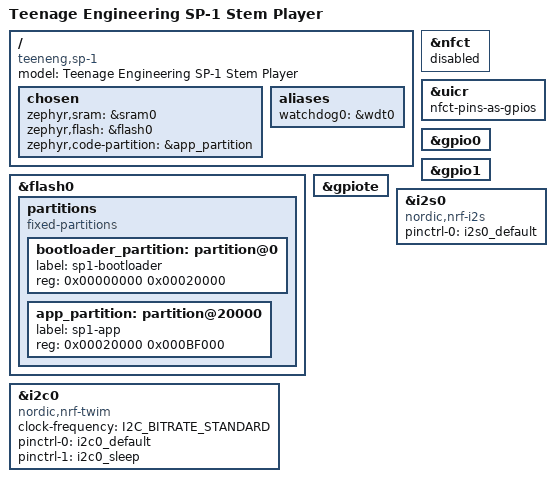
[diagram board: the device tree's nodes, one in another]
/dts-v1/;
#include <nordic/nrf52840_qiaa.dtsi>
#include "sp1-pinctrl.dtsi"

/ {
	model = "Teenage Engineering SP-1 Stem Player";
	compatible = "teeneng,sp-1";

	chosen {
		zephyr,sram = &sram0;
		zephyr,flash = &flash0;
		zephyr,code-partition = &app_partition;
	};

	aliases {
		watchdog0 = &wdt0;
	};
};

&flash0 {
	partitions {
		compatible = "fixed-partitions";
		#address-cells = <1>;
		#size-cells = <1>;

		bootloader_partition: partition@0 {
			label = "sp1-bootloader";
			reg = <0x00000000 0x00020000>;
		};

		app_partition: partition@20000 {
			label = "sp1-app";
			reg = <0x00020000 0x000BF000>;
		};
	};
};

&nfct {
	status = "disabled";
};

/* Reclaim NFC1/NFC2 (P0.09/P0.10) as GPIO — P0.09 is the TAS2505 reset line.
 * Writes UICR->NFCPINS; takes effect after the first boot following a flash. */
&uicr {
	nfct-pins-as-gpios;
};

&gpio0 {
	status = "okay";
};

&gpio1 {
	status = "okay";
};

&gpiote {
	status = "okay";
};

&i2c0 {
	compatible = "nordic,nrf-twim";
	status = "okay";
	clock-frequency = <I2C_BITRATE_STANDARD>;
	pinctrl-0 = <&i2c0_default>;
	pinctrl-1 = <&i2c0_sleep>;
	pinctrl-names = "default", "sleep";
};

&i2s0 {
	compatible = "nordic,nrf-i2s";
	status = "okay";
	pinctrl-0 = <&i2s0_default>;
	pinctrl-names = "default";
};
